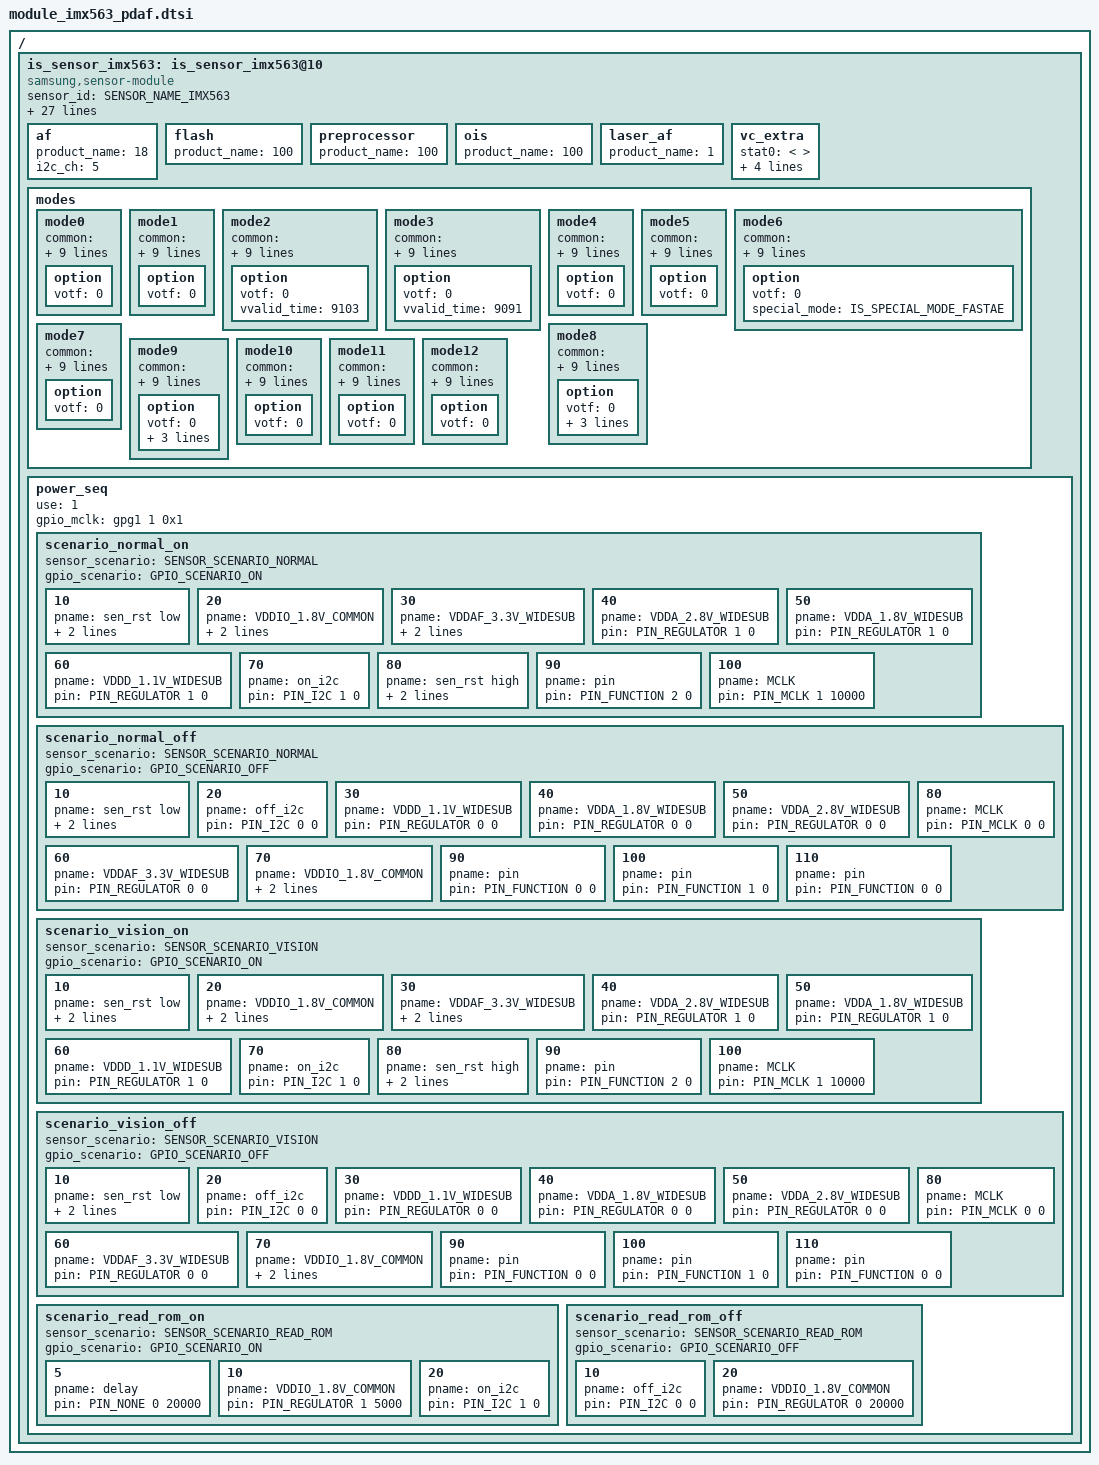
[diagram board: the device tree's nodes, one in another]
/*
 * SAMSUNG EXYNOSxxxx board camera device tree source
 *
 * Copyright (c) 2019 Samsung Electronics Co., Ltd.
 *		http://www.samsung.com
 *
 * This program is free software; you can redistribute it and/or modify
 * it under the terms of the GNU General Public License version 2 as
 * published by the Free Software Foundation.
 */

#include <dt-bindings/camera/exynos_is_dt.h>

/ {
	fragment@camera {
		target-path = "/";
		__overlay__ {
			is_sensor_imx563: is_sensor_imx563@10 {
				compatible = "samsung,sensor-module";

				/* common */
				sensor_id = <SENSOR_NAME_IMX563>;
				active_width = <4000>;
				active_height = <3000>;
				margin_left = <0>;
				margin_right = <0>;
				margin_top = <0>;
				margin_bottom = <0>;
				max_framerate = <480>;
				bitwidth = <10>;
				use_retention_mode = <SENSOR_RETENTION_UNSUPPORTED>;
				sensor_maker = "SONY";
				sensor_name = "IMX563";
				setfile_name = "setfile_imx563.bin";

				status = "okay";

				/* board */
				pinctrl-names = "pin0", "pin1", "pin2", "release";
				pinctrl-0 = <>;
				pinctrl-1 = <&sensor_mclk1_out>;
				pinctrl-2 = <&sensor_mclk1_fn>;
				pinctrl-3 = <>;

				position = <4>; /* Rear:0. Front:1, Tele:2 */
				id = <4>; /* is_sensor id */
				mclk_ch = <1>;
				mclk_freq = <19200>;
				sensor_i2c_ch = <4>; /* SENSOR_CONTROL_I2C4 */

				/* vendor */
				rom_type = <2>; /* ROM_TYPE_EEPROM */
				rom_id = <2>;
				rom_cal_index = <0>;
				rom_dualcal_id = <0>;
				rom_dualcal_index = <0>;

				/* peri */
				af {
					product_name = <18>; /* ACTUATOR_NAME_AK737X */
					i2c_ch = <5>; /* SENSOR_CONTROL_I2C5 */
				};

				flash {
					product_name = <100>;  /* NOTHING */
				};

				preprocessor {
					product_name = <100>; /* NOTHING */
				};

				ois {
					product_name = <100>; /* NOTHING */
				};

				laser_af {
					product_name = <1>; /* LASER_AF_NAME_VL53L5 */
				};

				vc_extra {
					/* ex) statX = <stat_type, sensor_mode, max_width, max_height, max_element> */
					stat0 = </* not avaliable */>;									/* VC_BUF_DATA_TYPE_SENSOR_STAT1 */
					stat1 = </*VC_STAT_TYPE_PDP_4_1_PDAF_STAT0*/ 1200 /*VC_SENSOR_MODE_2PD_MODE3*/ 102 4000 750 2>;	/* VC_BUF_DATA_TYPE_GENERAL_STAT1 */
					stat2 = </* not avaliable */>;									/* VC_BUF_DATA_TYPE_SENSOR_STAT2 */
					stat3 = </*VC_STAT_TYPE_PDP_4_1_PDAF_STAT1*/ 1201 /*VC_SENSOR_MODE_2PD_MODE3*/ 102 4000 750 2>;	/* VC_BUF_DATA_TYPE_GENERAL_STAT2 */
					stat_vc = <2>; /* STAT out VC after CSIS link */
				};

				/* sensor modes */
				/*
					SENSOR_IMX563_4000X3000_30FPS = 0, //7b_1
					SENSOR_IMX563_4000X3000_60FPS = 1, //7a_2
					SENSOR_IMX563_4000X2252_30FPS = 2, //8b_1
					SENSOR_IMX563_4000X2252_60FPS = 3, //9b_1
					SENSOR_IMX563_1984X1488_30FPS = 4, //10_3
					SENSOR_IMX563_3328X1872_120FPS = 5, //15_2
					SENSOR_IMX563_1008X756_120FPS = 6, //11_3
					SENSOR_IMX563_1984X1488_240FPS = 7, //12_2
					SENSOR_IMX563_2016X1136_480FPS = 8, //13_2
					SENSOR_IMX563_1280X720_480FPS = 9, //16_2
				*/
				modes {
						/* common = <width, height, fps, settle, mode, lane, speed, interleave, lrte, pd_mode> */
						/* vcX = <map, hwformat, width, height, hwformat, type, width, height> */
					mode0 {/* 7b_1 */
						common = <4000 3000 30 0 0 CSI_DATA_LANES_3 1896 CSI_MODE_VC_ONLY LRTE_ENABLE PD_MOD3>;
						vc0 = </* in */ 0 HW_FORMAT_RAW10 4000 3000	/* out */ HW_FORMAT_RAW10 VC_NOTHING 4000 3000>;
						vc1 = </* in */ 2 HW_FORMAT_UNKNOWN 0 0		/* out */ HW_FORMAT_UNKNOWN VC_NOTHING 0 0>;
						vc2 = </* in */ 1 HW_FORMAT_RAW10_POTF 4000 750	/* out */ HW_FORMAT_RAW10_POTF VC_TAILPDAF 4000 750>;
						vc3 = </* in */ 3 HW_FORMAT_UNKNOWN 0 0		/* out */ HW_FORMAT_UNKNOWN VC_NOTHING 0 0>;
						option { votf = <0>; };
					};
					mode1 {/* 7a_2 */
						common = <4000 3000 60 0 1 CSI_DATA_LANES_3 2944 CSI_MODE_VC_ONLY LRTE_ENABLE PD_MOD3>;
						vc0 = </* in */ 0 HW_FORMAT_RAW10 4000 3000	/* out */ HW_FORMAT_RAW10 VC_NOTHING 4000 3000>;
						vc1 = </* in */ 2 HW_FORMAT_UNKNOWN 0 0		/* out */ HW_FORMAT_UNKNOWN VC_NOTHING 0 0>;
						vc2 = </* in */ 1 HW_FORMAT_RAW10_POTF 4000 750	/* out */ HW_FORMAT_RAW10_POTF VC_TAILPDAF 4000 750>;
						vc3 = </* in */ 3 HW_FORMAT_UNKNOWN 0 0		/* out */ HW_FORMAT_UNKNOWN VC_NOTHING 0 0>;
						option { votf = <0>; };
					};
					mode2 {/* 8b_1 */
						common = <4000 2252 30 0 2 CSI_DATA_LANES_3 1896 CSI_MODE_VC_ONLY LRTE_ENABLE PD_MOD3>;
						vc0 = </* in */ 0 HW_FORMAT_RAW10 4000 2252	/* out */ HW_FORMAT_RAW10 VC_NOTHING 4000 2252>;
						vc1 = </* in */ 2 HW_FORMAT_UNKNOWN 0 0		/* out */ HW_FORMAT_UNKNOWN VC_NOTHING 0 0>;
						vc2 = </* in */ 1 HW_FORMAT_RAW10_POTF 4000 563	/* out */ HW_FORMAT_RAW10_POTF VC_TAILPDAF 4000 563>;
						vc3 = </* in */ 3 HW_FORMAT_UNKNOWN 0 0		/* out */ HW_FORMAT_UNKNOWN VC_NOTHING 0 0>;
						option { votf = <0>; vvalid_time = <9103>; };
					};
					mode3 {/* 9b_1 */
						common = <4000 2252 60 0 3 CSI_DATA_LANES_3 1896 CSI_MODE_VC_ONLY LRTE_ENABLE PD_MOD3>;
						vc0 = </* in */ 0 HW_FORMAT_RAW10 4000 2252	/* out */ HW_FORMAT_RAW10 VC_NOTHING 4000 2252>;
						vc1 = </* in */ 2 HW_FORMAT_UNKNOWN 0 0		/* out */ HW_FORMAT_UNKNOWN VC_NOTHING 0 0>;
						vc2 = </* in */ 1 HW_FORMAT_RAW10_POTF 4000 563	/* out */ HW_FORMAT_RAW10_POTF VC_TAILPDAF 4000 563>;
						vc3 = </* in */ 3 HW_FORMAT_UNKNOWN 0 0		/* out */ HW_FORMAT_UNKNOWN VC_NOTHING 0 0>;
						option { votf = <0>; vvalid_time = <9091>; };
					};
					mode4 {/* 10_3 */
						common = <1984 1488 30 0 4 CSI_DATA_LANES_3 2297 CSI_MODE_VC_ONLY LRTE_ENABLE PD_NONE>;
						vc0 = </* in */ 0 HW_FORMAT_RAW10 1984 1488	/* out */ HW_FORMAT_RAW10 VC_NOTHING 1984 1488>;
						vc1 = </* in */ 1 HW_FORMAT_UNKNOWN 0 0		/* out */ HW_FORMAT_UNKNOWN VC_NOTHING 0 0>;
						vc2 = </* in */ 2 HW_FORMAT_UNKNOWN 0 0		/* out */ HW_FORMAT_UNKNOWN VC_NOTHING 0 0>;
						vc3 = </* in */ 3 HW_FORMAT_UNKNOWN 0 0		/* out */ HW_FORMAT_UNKNOWN VC_NOTHING 0 0>;
						option { votf = <0>; };
					};
					mode5 {/* 15_2 */
						common = <3328 1872 120 0 5 CSI_DATA_LANES_3 2944 CSI_MODE_VC_ONLY LRTE_ENABLE PD_MOD3>;
						vc0 = </* in */ 0 HW_FORMAT_RAW10 3328 1872	/* out */ HW_FORMAT_RAW10 VC_NOTHING 3328 1872>;
						vc1 = </* in */ 2 HW_FORMAT_UNKNOWN 0 0		/* out */ HW_FORMAT_UNKNOWN VC_NOTHING 0 0>;
						vc2 = </* in */ 1 HW_FORMAT_RAW10_POTF 3328 468	/* out */ HW_FORMAT_RAW10_POTF VC_TAILPDAF 3328 468>;
						vc3 = </* in */ 3 HW_FORMAT_UNKNOWN 0 0		/* out */ HW_FORMAT_UNKNOWN VC_NOTHING 0 0>;
						option { votf = <0>; };
					};
					mode6 {/* 11_3 */
						common = <1008 756 120 0 6 CSI_DATA_LANES_3 2297 CSI_MODE_VC_ONLY LRTE_ENABLE PD_MOD3>;
						vc0 = </* in */ 0 HW_FORMAT_RAW10 1008 756	/* out */ HW_FORMAT_RAW10 VC_NOTHING 1008 756>;
						vc1 = </* in */ 2 HW_FORMAT_UNKNOWN 0 0		/* out */ HW_FORMAT_UNKNOWN VC_NOTHING 0 0>;
						vc2 = </* in */ 1 HW_FORMAT_RAW10_POTF 1008 189	/* out */ HW_FORMAT_RAW10_POTF VC_TAILPDAF 1000 189>;
						vc3 = </* in */ 3 HW_FORMAT_UNKNOWN 0 0		/* out */ HW_FORMAT_UNKNOWN VC_NOTHING 0 0>;
						option { votf = <0>; special_mode = <IS_SPECIAL_MODE_FASTAE>; };
					};
					mode7 {/* 12_2 */
						common = <1984 1488 240 0 7 CSI_DATA_LANES_3 2944 CSI_MODE_VC_ONLY LRTE_ENABLE PD_MOD3>;
						vc0 = </* in */ 0 HW_FORMAT_RAW10 1984 1488	/* out */ HW_FORMAT_RAW10 VC_NOTHING 1984 1488>;
						vc1 = </* in */ 2 HW_FORMAT_UNKNOWN 0 0		/* out */ HW_FORMAT_UNKNOWN VC_NOTHING 0 0>;
						vc2 = </* in */ 1 HW_FORMAT_RAW10_POTF 1984 372	/* out */ HW_FORMAT_RAW10_POTF VC_TAILPDAF 1984 372>;
						vc3 = </* in */ 3 HW_FORMAT_UNKNOWN 0 0		/* out */ HW_FORMAT_UNKNOWN VC_NOTHING 0 0>;
						option { votf = <0>; };
					};
					mode8 {/* 13_2 */
						common = <2016 1136 480 0 8 CSI_DATA_LANES_3 2944 CSI_MODE_VC_DT LRTE_ENABLE PD_NONE EX_DUALFPS_480>;
						vc0 = </* in */ 0 HW_FORMAT_RAW10 2016 1136	/* out */ HW_FORMAT_RAW10 VC_FRO 2016 1136>;
						vc1 = </* in */ 1 HW_FORMAT_UNKNOWN 0 0		/* out */ HW_FORMAT_UNKNOWN VC_NOTHING 0 0>;
						vc2 = </* in */ 0 HW_FORMAT_EMBEDDED_8BIT 2520 2	/* out */ HW_FORMAT_EMBEDDED_8BIT VC_EMBEDDED 2520 2>;
						vc3 = </* in */ 2 HW_FORMAT_UNKNOWN 0 0		/* out */ HW_FORMAT_UNKNOWN VC_NOTHING 0 0>;
						option { votf = <0>; vvalid_time = <1683>; req_vvalid_time = <10000>; fid_loc = <0 33>; };
					};
					mode9 {/* 16_2 */
						common = <1280 720 480 0 9 CSI_DATA_LANES_3 2944 CSI_MODE_VC_DT LRTE_ENABLE PD_NONE EX_DUALFPS_480>;
						vc0 = </* in */ 0 HW_FORMAT_RAW10 1280 720	/* out */ HW_FORMAT_RAW10 VC_FRO 1280 720>;
						vc1 = </* in */ 1 HW_FORMAT_UNKNOWN 0 0		/* out */ HW_FORMAT_UNKNOWN VC_NOTHING 0 0>;
						vc2 = </* in */ 0 HW_FORMAT_EMBEDDED_8BIT 1600 2	/* out */ HW_FORMAT_EMBEDDED_8BIT VC_EMBEDDED 1600 2>;
						vc3 = </* in */ 3 HW_FORMAT_UNKNOWN 0 0		/* out */ HW_FORMAT_UNKNOWN VC_NOTHING 0 0>;
						option { votf = <0>; vvalid_time = <1123>; req_vvalid_time = <10000>; fid_loc = <0 33>; };
					};
					mode10 {/* 17_3 */
						common = <2000 1500 120 0 10 CSI_DATA_LANES_3 2297 CSI_MODE_VC_ONLY LRTE_ENABLE PD_MOD3>;
						vc0 = </* in */ 0 HW_FORMAT_RAW10 2000 1500	/* out */ HW_FORMAT_RAW10 VC_NOTHING 2000 1500>;
						vc1 = </* in */ 2 HW_FORMAT_UNKNOWN 0 0		/* out */ HW_FORMAT_UNKNOWN VC_NOTHING 0 0>;
						vc2 = </* in */ 1 HW_FORMAT_RAW10_POTF 2000 375	/* out */ HW_FORMAT_RAW10_POTF VC_TAILPDAF 2000 375>;
						vc3 = </* in */ 3 HW_FORMAT_UNKNOWN 0 0		/* out */ HW_FORMAT_UNKNOWN VC_NOTHING 0 0>;
						option { votf = <0>; };
					};
					mode11 {/* 7b_1_t1 */
						common = <2800 2100 30 0 11 CSI_DATA_LANES_3 1896 CSI_MODE_VC_ONLY LRTE_ENABLE PD_MOD3>;
						vc0 = </* in */ 0 HW_FORMAT_RAW10 2800 2100	/* out */ HW_FORMAT_RAW10 VC_NOTHING 2800 2100>;
						vc1 = </* in */ 2 HW_FORMAT_UNKNOWN 0 0		/* out */ HW_FORMAT_UNKNOWN VC_NOTHING 0 0>;
						vc2 = </* in */ 1 HW_FORMAT_RAW10_POTF 2800 525	/* out */ HW_FORMAT_RAW10_POTF VC_TAILPDAF 2800 525>;
						vc3 = </* in */ 3 HW_FORMAT_UNKNOWN 0 0		/* out */ HW_FORMAT_UNKNOWN VC_NOTHING 0 0>;
						option { votf = <0>; };
					};
					mode12 {/* 7b_1_t2 */
						common = <2800 2100 24 0 12 CSI_DATA_LANES_3 1896 CSI_MODE_VC_ONLY LRTE_ENABLE PD_MOD3>;
						vc0 = </* in */ 0 HW_FORMAT_RAW10 2800 2100	/* out */ HW_FORMAT_RAW10 VC_NOTHING 2800 2100>;
						vc1 = </* in */ 2 HW_FORMAT_UNKNOWN 0 0		/* out */ HW_FORMAT_UNKNOWN VC_NOTHING 0 0>;
						vc2 = </* in */ 1 HW_FORMAT_RAW10_POTF 2800 525	/* out */ HW_FORMAT_RAW10_POTF VC_TAILPDAF 2800 525>;
						vc3 = </* in */ 3 HW_FORMAT_UNKNOWN 0 0		/* out */ HW_FORMAT_UNKNOWN VC_NOTHING 0 0>;
						option { votf = <0>; };
					};
				};

				power_seq {
					use = <1>;
					gpio_mclk = <&gpg1 1 0x1>;
					scenario_normal_on {
						sensor_scenario = <SENSOR_SCENARIO_NORMAL>;
						gpio_scenario = <GPIO_SCENARIO_ON>;

						/* A start node number should be over the 10 for reserved number 0~9. */
						/* pname = "name"; pin = <act value dealy voltage>; gpio = <gpx# # 0x1>; */
						10 { pname = "sen_rst low"; pin = <PIN_OUTPUT 0 0>; gpio = <&gpc0 1 0x1>; };
						20 { pname = "VDDIO_1.8V_COMMON"; pin = <PIN_REGULATOR 1 0>; share = <SRT_ACQUIRE SHARED_PIN0 1>; };
						30 { pname = "VDDAF_3.3V_WIDESUB"; pin = <PIN_REGULATOR 1 0>; actuator_i2c_delay = <3000>; };
						40 { pname = "VDDA_2.8V_WIDESUB"; pin = <PIN_REGULATOR 1 0>; };
						50 { pname = "VDDA_1.8V_WIDESUB"; pin = <PIN_REGULATOR 1 0>; };
						60 { pname = "VDDD_1.1V_WIDESUB"; pin = <PIN_REGULATOR 1 0>; };
						70 { pname = "on_i2c"; pin = <PIN_I2C 1 0>; };
						80 { pname = "sen_rst high"; pin = <PIN_OUTPUT 1 0>; gpio = <&gpc0 1 0x1>; };
						90 { pname = "pin"; pin = <PIN_FUNCTION 2 0>; };
						100 { pname = "MCLK"; pin = <PIN_MCLK 1 10000>; };
					};

					scenario_normal_off {
						sensor_scenario = <SENSOR_SCENARIO_NORMAL>;
						gpio_scenario = <GPIO_SCENARIO_OFF>;

						/* A start node number should be over the 10 for reserved number 0~9. */
						/* pname = "name"; pin = <act value dealy voltage>; gpio = <gpx# # 0x1>; */
						10 { pname = "sen_rst low"; pin = <PIN_OUTPUT 0 0>; gpio = <&gpc0 1 0x1>; };
						20 { pname = "off_i2c"; pin = <PIN_I2C 0 0>; };
						30 { pname = "VDDD_1.1V_WIDESUB"; pin = <PIN_REGULATOR 0 0>; };
						40 { pname = "VDDA_1.8V_WIDESUB"; pin = <PIN_REGULATOR 0 0>; };
						50 { pname = "VDDA_2.8V_WIDESUB"; pin = <PIN_REGULATOR 0 0>; };
						60 { pname = "VDDAF_3.3V_WIDESUB"; pin = <PIN_REGULATOR 0 0>; };
						70 { pname = "VDDIO_1.8V_COMMON"; pin = <PIN_REGULATOR 0 0>; share = <SRT_RELEASE SHARED_PIN0 0>; };
						80 { pname = "MCLK"; pin = <PIN_MCLK 0 0>; };
						90 { pname = "pin"; pin = <PIN_FUNCTION 0 0>; };
						100 { pname = "pin"; pin = <PIN_FUNCTION 1 0>; };
						110 { pname = "pin"; pin = <PIN_FUNCTION 0 0>; };
					};

					scenario_vision_on {
						sensor_scenario = <SENSOR_SCENARIO_VISION>;
						gpio_scenario = <GPIO_SCENARIO_ON>;

						/* A start node number should be over the 10 for reserved number 0~9. */
						/* pname = "name"; pin = <act value dealy voltage>; gpio = <gpx# # 0x1>; */
						10 { pname = "sen_rst low"; pin = <PIN_OUTPUT 0 0>; gpio = <&gpc0 1 0x1>; };
						20 { pname = "VDDIO_1.8V_COMMON"; pin = <PIN_REGULATOR 1 0>; share = <SRT_ACQUIRE SHARED_PIN0 1>; };
						30 { pname = "VDDAF_3.3V_WIDESUB"; pin = <PIN_REGULATOR 1 0>; actuator_i2c_delay = <3000>; };
						40 { pname = "VDDA_2.8V_WIDESUB"; pin = <PIN_REGULATOR 1 0>; };
						50 { pname = "VDDA_1.8V_WIDESUB"; pin = <PIN_REGULATOR 1 0>; };
						60 { pname = "VDDD_1.1V_WIDESUB"; pin = <PIN_REGULATOR 1 0>; };
						70 { pname = "on_i2c"; pin = <PIN_I2C 1 0>; };
						80 { pname = "sen_rst high"; pin = <PIN_OUTPUT 1 0>; gpio = <&gpc0 1 0x1>; };
						90 { pname = "pin"; pin = <PIN_FUNCTION 2 0>; };
						100 { pname = "MCLK"; pin = <PIN_MCLK 1 10000>; };
					};

					scenario_vision_off {
						sensor_scenario = <SENSOR_SCENARIO_VISION>;
						gpio_scenario = <GPIO_SCENARIO_OFF>;

						/* A start node number should be over the 10 for reserved number 0~9. */
						/* pname = "name"; pin = <act value dealy voltage>; gpio = <gpx# # 0x1>; */
						10 { pname = "sen_rst low"; pin = <PIN_OUTPUT 0 0>; gpio = <&gpc0 1 0x1>; };
						20 { pname = "off_i2c"; pin = <PIN_I2C 0 0>; };
						30 { pname = "VDDD_1.1V_WIDESUB"; pin = <PIN_REGULATOR 0 0>; };
						40 { pname = "VDDA_1.8V_WIDESUB"; pin = <PIN_REGULATOR 0 0>; };
						50 { pname = "VDDA_2.8V_WIDESUB"; pin = <PIN_REGULATOR 0 0>; };
						60 { pname = "VDDAF_3.3V_WIDESUB"; pin = <PIN_REGULATOR 0 0>; };
						70 { pname = "VDDIO_1.8V_COMMON"; pin = <PIN_REGULATOR 0 0>; share = <SRT_RELEASE SHARED_PIN0 0>; };
						80 { pname = "MCLK"; pin = <PIN_MCLK 0 0>; };
						90 { pname = "pin"; pin = <PIN_FUNCTION 0 0>; };
						100 { pname = "pin"; pin = <PIN_FUNCTION 1 0>; };
						110 { pname = "pin"; pin = <PIN_FUNCTION 0 0>; };
					};

					scenario_read_rom_on {
						sensor_scenario = <SENSOR_SCENARIO_READ_ROM>;
						gpio_scenario = <GPIO_SCENARIO_ON>;

						/* A start node number should be over the 10 for reserved number 0~9. */
						/* pname = "name"; pin = <act value dealy voltage>; gpio = <gpx# # 0x1>; */
						5 { pname = "delay"; pin = <PIN_NONE 0 20000>; };
						10 { pname = "VDDIO_1.8V_COMMON"; pin = <PIN_REGULATOR 1 5000>; };
						20 { pname = "on_i2c"; pin = <PIN_I2C 1 0>; };
					};

					scenario_read_rom_off {
						sensor_scenario = <SENSOR_SCENARIO_READ_ROM>;
						gpio_scenario = <GPIO_SCENARIO_OFF>;

						/* A start node number should be over the 10 for reserved number 0~9. */
						/* pname = "name"; pin = <act value dealy voltage>; gpio = <gpx# # 0x1>; */
						10 { pname = "off_i2c"; pin = <PIN_I2C 0 0>; };
						20 { pname = "VDDIO_1.8V_COMMON"; pin = <PIN_REGULATOR 0 20000>; };
					};
				};
			};
		}; /* end of __overlay__ */
	}; /* end of fragment */
}; /* end of root */
